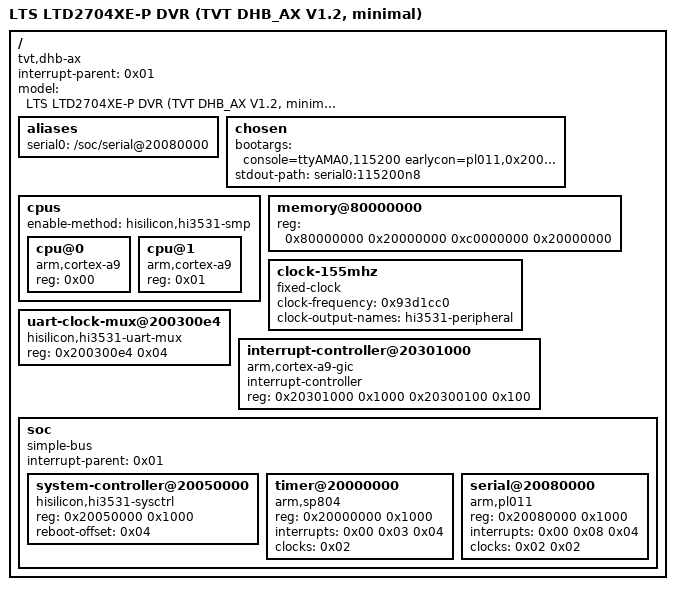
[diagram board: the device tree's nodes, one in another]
/dts-v1/;

/ {
	compatible = "tvt,dhb-ax", "hisilicon,hi3531";
	#address-cells = <0x01>;
	#size-cells = <0x01>;
	interrupt-parent = <0x01>;
	model = "LTS LTD2704XE-P DVR (TVT DHB_AX V1.2, minimal)";

	aliases {
		serial0 = "/soc/serial@20080000";
	};

	chosen {
		bootargs = "console=ttyAMA0,115200 earlycon=pl011,0x20080000 keep_bootcon ignore_loglevel rdinit=/init";
		stdout-path = "serial0:115200n8";
	};

	cpus {
		#address-cells = <0x01>;
		#size-cells = <0x00>;
		enable-method = "hisilicon,hi3531-smp";

		cpu@0 {
			compatible = "arm,cortex-a9";
			device_type = "cpu";
			reg = <0x00>;
		};

		cpu@1 {
			compatible = "arm,cortex-a9";
			device_type = "cpu";
			reg = <0x01>;
		};
	};

	memory@80000000 {
		device_type = "memory";
		reg = <0x80000000 0x20000000 0xc0000000 0x20000000>;
	};

	clock-155mhz {
		compatible = "fixed-clock";
		#clock-cells = <0x00>;
		clock-frequency = <0x93d1cc0>;
		clock-output-names = "hi3531-peripheral";
		phandle = <0x02>;
	};

	uart-clock-mux@200300e4 {
		compatible = "hisilicon,hi3531-uart-mux";
		reg = <0x200300e4 0x04>;
	};

	interrupt-controller@20301000 {
		compatible = "arm,cortex-a9-gic";
		#interrupt-cells = <0x03>;
		#address-cells = <0x00>;
		interrupt-controller;
		reg = <0x20301000 0x1000 0x20300100 0x100>;
		phandle = <0x01>;
	};

	soc {
		compatible = "simple-bus";
		#address-cells = <0x01>;
		#size-cells = <0x01>;
		interrupt-parent = <0x01>;
		ranges;

		system-controller@20050000 {
			compatible = "hisilicon,hi3531-sysctrl", "hisilicon,sysctrl";
			reg = <0x20050000 0x1000>;
			reboot-offset = <0x04>;
		};

		timer@20000000 {
			compatible = "arm,sp804", "arm,primecell";
			reg = <0x20000000 0x1000>;
			interrupts = <0x00 0x03 0x04>;
			clocks = <0x02>;
			clock-names = "apb_pclk";
		};

		serial@20080000 {
			compatible = "arm,pl011", "arm,primecell";
			reg = <0x20080000 0x1000>;
			interrupts = <0x00 0x08 0x04>;
			clocks = <0x02 0x02>;
			clock-names = "uartclk", "apb_pclk";
		};
	};
};
